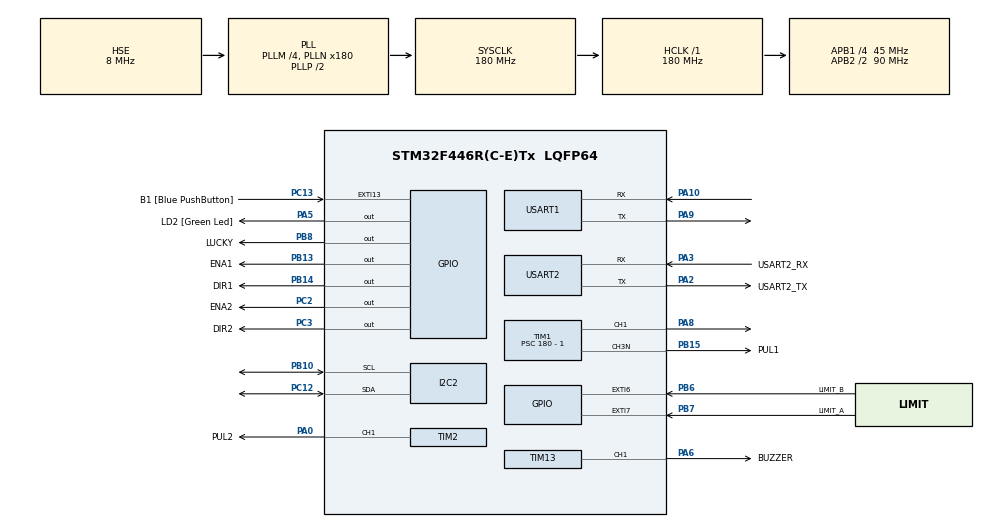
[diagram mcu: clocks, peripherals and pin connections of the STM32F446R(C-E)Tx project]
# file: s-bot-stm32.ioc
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Dma.I2C2_TX.3.Direction=DMA_MEMORY_TO_PERIPH
Dma.I2C2_TX.3.FIFOMode=DMA_FIFOMODE_DISABLE
Dma.I2C2_TX.3.Instance=DMA1_Stream7
Dma.I2C2_TX.3.MemDataAlignment=DMA_MDATAALIGN_BYTE
Dma.I2C2_TX.3.MemInc=DMA_MINC_ENABLE
Dma.I2C2_TX.3.Mode=DMA_NORMAL
Dma.I2C2_TX.3.PeriphDataAlignment=DMA_PDATAALIGN_BYTE
Dma.I2C2_TX.3.PeriphInc=DMA_PINC_DISABLE
Dma.I2C2_TX.3.Priority=DMA_PRIORITY_LOW
Dma.Request0=USART2_RX
Dma.Request1=USART1_TX
Dma.Request2=USART2_TX
Dma.Request3=I2C2_TX
Dma.Request4=USART1_RX
Dma.USART1_RX.4.Direction=DMA_PERIPH_TO_MEMORY
Dma.USART1_RX.4.FIFOMode=DMA_FIFOMODE_DISABLE
Dma.USART1_RX.4.Instance=DMA2_Stream2
Dma.USART1_RX.4.MemDataAlignment=DMA_MDATAALIGN_BYTE
Dma.USART1_RX.4.MemInc=DMA_MINC_ENABLE
Dma.USART1_RX.4.Mode=DMA_NORMAL
Dma.USART1_RX.4.PeriphDataAlignment=DMA_PDATAALIGN_BYTE
Dma.USART1_RX.4.PeriphInc=DMA_PINC_DISABLE
Dma.USART1_RX.4.Priority=DMA_PRIORITY_LOW
Dma.USART1_TX.1.Direction=DMA_MEMORY_TO_PERIPH
Dma.USART1_TX.1.FIFOMode=DMA_FIFOMODE_DISABLE
Dma.USART1_TX.1.Instance=DMA2_Stream7
Dma.USART1_TX.1.MemDataAlignment=DMA_MDATAALIGN_BYTE
Dma.USART1_TX.1.MemInc=DMA_MINC_ENABLE
Dma.USART1_TX.1.Mode=DMA_NORMAL
Dma.USART1_TX.1.PeriphDataAlignment=DMA_PDATAALIGN_BYTE
Dma.USART1_TX.1.PeriphInc=DMA_PINC_DISABLE
Dma.USART1_TX.1.Priority=DMA_PRIORITY_LOW
Dma.USART2_RX.0.Direction=DMA_PERIPH_TO_MEMORY
Dma.USART2_RX.0.FIFOMode=DMA_FIFOMODE_DISABLE
Dma.USART2_RX.0.Instance=DMA1_Stream5
Dma.USART2_RX.0.MemDataAlignment=DMA_MDATAALIGN_BYTE
Dma.USART2_RX.0.MemInc=DMA_MINC_ENABLE
Dma.USART2_RX.0.Mode=DMA_NORMAL
Dma.USART2_RX.0.PeriphDataAlignment=DMA_PDATAALIGN_BYTE
Dma.USART2_RX.0.PeriphInc=DMA_PINC_DISABLE
Dma.USART2_RX.0.Priority=DMA_PRIORITY_LOW
Dma.USART2_TX.2.Direction=DMA_MEMORY_TO_PERIPH
Dma.USART2_TX.2.FIFOMode=DMA_FIFOMODE_DISABLE
Dma.USART2_TX.2.Instance=DMA1_Stream6
Dma.USART2_TX.2.MemDataAlignment=DMA_MDATAALIGN_BYTE
Dma.USART2_TX.2.MemInc=DMA_MINC_ENABLE
Dma.USART2_TX.2.Mode=DMA_NORMAL
Dma.USART2_TX.2.PeriphDataAlignment=DMA_PDATAALIGN_BYTE
Dma.USART2_TX.2.PeriphInc=DMA_PINC_DISABLE
Dma.USART2_TX.2.Priority=DMA_PRIORITY_LOW
FREERTOS.Tasks01=LEDblinkTask,24,128,LEDblink,Default,NULL,Dynamic,NULL,NULL;OLEDdisplayTask,8,128,OLEDdisplay,As weak,NULL,Dynamic,NULL,NULL;StepperTask,8,128,Stepper,As weak,NULL,Dynamic,NULL,NULL;RobotStateTask,40,300,StateUpdate,As weak,NULL,Dynamic,NULL,NULL
FREERTOS.Timers01=OLED_Tx_Timeout,OLED_Tx_Timeout_Callback,osTimerOnce,As weak,NULL,Dynamic,NULL;OLED_Warning_Timeout,OLED_Warning_Timeout_Callback,osTimerOnce,As weak,NULL,Dynamic,NULL;OLED_Rx_Timeout,OLED_Rx_Timeout_Callback,osTimerOnce,As weak,NULL,Dynamic,NULL;USB_Hello,USB_Hello_Callback,osTimerPeriodic,As weak,NULL,Dynamic,NULL;Buzzer_Timeout,Buzzer_Timeout_Callback,osTimerOnce,As weak,NULL,Dynamic,NULL;Force_Sensor_Request_Timeout,Force_Sensor_Request_Timeout_Callback,osTimerPeriodic,As weak,NULL,Dynamic,NULL
Mcu.Family=STM32F4
Mcu.Name=STM32F446R(C-E)Tx
Mcu.Package=LQFP64
NVIC.DMA1_Stream5_IRQn=true\:5\:0\:false\:false\:true\:true\:false\:true\:true
NVIC.DMA1_Stream6_IRQn=true\:5\:0\:false\:false\:true\:true\:false\:true\:true
NVIC.DMA1_Stream7_IRQn=true\:5\:0\:false\:false\:true\:true\:false\:true\:true
NVIC.DMA2_Stream2_IRQn=true\:5\:0\:false\:false\:true\:true\:false\:true\:true
NVIC.DMA2_Stream7_IRQn=true\:5\:0\:false\:false\:true\:true\:false\:true\:true
NVIC.EXTI15_10_IRQn=true\:5\:0\:false\:false\:true\:true\:true\:true\:true
NVIC.EXTI9_5_IRQn=true\:5\:0\:true\:false\:true\:false\:true\:true\:true
NVIC.I2C2_EV_IRQn=true\:5\:0\:false\:false\:true\:true\:true\:true\:true
NVIC.PriorityGroup=NVIC_PRIORITYGROUP_4
NVIC.TIM1_BRK_TIM9_IRQn=true\:5\:0\:false\:false\:true\:true\:true\:true\:true
NVIC.TIM1_CC_IRQn=true\:5\:0\:false\:false\:true\:true\:true\:true\:true
NVIC.TIM1_UP_TIM10_IRQn=true\:5\:0\:false\:false\:true\:true\:true\:true\:true
NVIC.TIM2_IRQn=true\:5\:0\:false\:false\:true\:true\:true\:true\:true
NVIC.TIM8_TRG_COM_TIM14_IRQn=true\:15\:0\:false\:false\:true\:false\:false\:true\:true
NVIC.TimeBase=TIM8_TRG_COM_TIM14_IRQn
NVIC.TimeBaseIP=TIM14
NVIC.USART1_IRQn=true\:5\:0\:false\:false\:true\:true\:true\:true\:true
NVIC.USART2_IRQn=true\:5\:0\:false\:false\:true\:true\:true\:true\:true
PA0-WKUP.GPIO_Label=PUL2
PA0-WKUP.GPIO_PuPd=GPIO_PULLDOWN
PA0-WKUP.Signal=S_TIM2_CH1_ETR
PA10.Mode=Asynchronous
PA10.Signal=USART1_RX
PA13.GPIO_Label=TMS
PA13.Mode=Serial_Wire
PA13.Signal=SYS_JTMS-SWDIO
PA14.GPIO_Label=TCK
PA14.Mode=Serial_Wire
PA14.Signal=SYS_JTCK-SWCLK
PA2.GPIO_Label=USART2_TX
PA2.Mode=Asynchronous
PA2.Signal=USART2_TX
PA3.GPIO_Label=USART2_RX
PA3.Mode=Asynchronous
PA3.Signal=USART2_RX
PA5.GPIO_Label=LD2 [Green Led]
PA5.Signal=GPIO_Output
PA6.GPIO_Label=BUZZER
PA6.Signal=S_TIM13_CH1
PA8.GPIO_PuPd=GPIO_PULLDOWN
PA8.Signal=S_TIM1_CH1
PA9.Mode=Asynchronous
PA9.Signal=USART1_TX
PB10.Mode=I2C
PB10.Signal=I2C2_SCL
PB13.GPIO_Label=ENA1
PB13.Signal=GPIO_Output
PB14.GPIO_Label=DIR1
PB14.Signal=GPIO_Output
PB15.GPIO_Label=PUL1
PB15.GPIO_PuPd=GPIO_PULLDOWN
PB15.Mode=PWM Generation3 CH3N
PB15.Signal=TIM1_CH3N
PB3.GPIO_Label=SWO
PB3.Signal=SYS_JTDO-SWO
PB6.GPIO_Label=LIMIT_B
PB6.GPIO_PuPd=GPIO_PULLUP
PB6.Signal=GPXTI6
PB7.GPIO_Label=LIMIT_A
PB7.GPIO_ModeDefaultEXTI=GPIO_MODE_IT_FALLING
PB7.GPIO_PuPd=GPIO_PULLUP
PB7.Signal=GPXTI7
PB8.GPIO_Label=LUCKY
PB8.Signal=GPIO_Output
PC12.Mode=I2C
PC12.Signal=I2C2_SDA
PC13.GPIO_Label=B1 [Blue PushButton]
PC13.GPIO_ModeDefaultEXTI=GPIO_MODE_IT_FALLING
PC13.Signal=GPXTI13
PC14-OSC32_IN.Mode=LSE-External-Oscillator
PC14-OSC32_IN.Signal=RCC_OSC32_IN
PC15-OSC32_OUT.Mode=LSE-External-Oscillator
PC15-OSC32_OUT.Signal=RCC_OSC32_OUT
PC2.GPIO_Label=ENA2
PC2.Signal=GPIO_Output
PC3.GPIO_Label=DIR2
PC3.Signal=GPIO_Output
PH0-OSC_IN.Mode=HSE-External-Oscillator
PH0-OSC_IN.Signal=RCC_OSC_IN
PH1-OSC_OUT.Mode=HSE-External-Oscillator
PH1-OSC_OUT.Signal=RCC_OSC_OUT
ProjectManager.HeapSize=0x200
ProjectManager.StackSize=0x400
ProjectManager.TargetToolchain=STM32CubeIDE
RCC.48MHZClocksFreq_Value=84000000
RCC.AHBFreq_Value=180000000
RCC.APB1CLKDivider=RCC_HCLK_DIV4
RCC.APB1Freq_Value=45000000
RCC.APB1TimFreq_Value=90000000
RCC.APB2CLKDivider=RCC_HCLK_DIV2
RCC.APB2Freq_Value=90000000
RCC.APB2TimFreq_Value=180000000
RCC.CortexFreq_Value=180000000
RCC.FLatency-AdvancedSettings=FLASH_LATENCY_5
RCC.HCLKFreq_Value=180000000
RCC.HSE_VALUE=8000000
RCC.HSI_VALUE=16000000
RCC.PLLM=4
RCC.PLLN=180
RCC.PLLSourceVirtual=RCC_PLLSOURCE_HSE
RCC.SYSCLKFreq_VALUE=180000000
RCC.SYSCLKSource=RCC_SYSCLKSOURCE_PLLCLK
RCC.USBFreq_Value=180000000
RCC.VCOOutputFreq_Value=360000000
SH.S_TIM13_CH1.0=TIM13_CH1,PWM Generation1 CH1
SH.S_TIM1_CH1.0=TIM1_CH1,PWM Generation1 CH1
SH.S_TIM2_CH1_ETR.0=TIM2_CH1,PWM Generation1 CH1
TIM1.Channel-PWM\ Generation1\ CH1=TIM_CHANNEL_1
TIM1.Channel-PWM\ Generation3\ CH3N=TIM_CHANNEL_3
TIM1.OC3Preload_PWM=DISABLE
TIM1.OCFastMode_PWM-PWM\ Generation3\ CH3N=TIM_OCFAST_ENABLE
TIM1.OCMode_PWM-PWM\ Generation1\ CH1=TIM_OCMODE_PWM2
TIM1.OCMode_PWM-PWM\ Generation3\ CH3N=TIM_OCMODE_PWM2
TIM1.OCNPolarity_3=TIM_OCNPOLARITY_LOW
TIM1.OCPolarity_1=TIM_OCPOLARITY_LOW
TIM1.Period=100 - 1
TIM1.Prescaler=180 - 1
TIM1.Pulse-PWM\ Generation1\ CH1=10
TIM1.Pulse-PWM\ Generation3\ CH3N=10
TIM1.TIM_MasterOutputTrigger=TIM_TRGO_RESET
TIM13.Channel=TIM_CHANNEL_1
TIM13.Period=256 - 1
TIM13.Prescaler=256 - 1
TIM13.Pulse=10
TIM2.Channel-PWM\ Generation1\ CH1=TIM_CHANNEL_1
TIM2.CounterMode=TIM_COUNTERMODE_CENTERALIGNED1
TIM2.OCMode_PWM-PWM\ Generation1\ CH1=TIM_OCMODE_PWM2
TIM2.OCPolarity_1=TIM_OCPOLARITY_LOW
TIM2.Period=1000 - 1
TIM2.Prescaler=180 - 1
TIM2.Pulse-PWM\ Generation1\ CH1=10
USART1.VirtualMode=VM_ASYNC
USART2.VirtualMode=VM_ASYNC
VP_FREERTOS_VS_CMSIS_V2.Mode=CMSIS_V2
VP_SYS_VS_tim14.Mode=TIM14
VP_TIM13_VS_ClockSourceINT.Mode=Enable_Timer
VP_TIM1_VS_ClockSourceINT.Mode=Internal
VP_TIM2_VS_ClockSourceINT.Mode=Internal
board=NUCLEO-F446RE

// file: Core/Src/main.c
/* USER CODE BEGIN Header */
/**
 ******************************************************************************
 * @file           : main.c
 * @brief          : Main program body
 ******************************************************************************
 * @attention
 *
 * Copyright (c) 2022 STMicroelectronics.
 * All rights reserved.
 *
 * This software is licensed under terms that can be found in the LICENSE file
 * in the root directory of this software component.
 * If no LICENSE file comes with this software, it is provided AS-IS.
 *
 ******************************************************************************
 */
/* USER CODE END Header */
#include "main.h"
#include "cmsis_os.h"
#include "dma.h"
#include "i2c.h"
#include "tim.h"
#include "usart.h"
#include "gpio.h"

/* USER CODE BEGIN Includes */
#include "robot.h"
/* USER CODE END Includes */

void SystemClock_Config(void);
void MX_FREERTOS_Init(void);

int main(void)
{

  /* MCU Configuration--------------------------------------------------------*/

  /* Reset of all peripherals, Initializes the Flash interface and the Systick. */
  HAL_Init();

  /* Configure the system clock */
  SystemClock_Config();

  /* Initialize all configured peripherals */
  MX_GPIO_Init();
  MX_DMA_Init();
  MX_I2C2_Init();
  MX_USART1_UART_Init();
  MX_USART2_UART_Init();
  MX_TIM13_Init();
  MX_TIM1_Init();
  MX_TIM2_Init();
  /* USER CODE BEGIN 2 */
  USBserial_Init();
  OLED_Init();
  State_Init();
  /* USER CODE END 2 */

  /* Init scheduler */
  osKernelInitialize();  /* Call init function for freertos objects (in freertos.c) */
  MX_FREERTOS_Init();

  /* Start scheduler */
  osKernelStart();

  /* We should never get here as control is now taken by the scheduler */
  /* Infinite loop */
  while (1)
  {

  }
}

void SystemClock_Config(void)
{
  RCC_OscInitTypeDef RCC_OscInitStruct = {0};
  RCC_ClkInitTypeDef RCC_ClkInitStruct = {0};

  /** Configure the main internal regulator output voltage
  */
  __HAL_RCC_PWR_CLK_ENABLE();
  __HAL_PWR_VOLTAGESCALING_CONFIG(PWR_REGULATOR_VOLTAGE_SCALE1);

  /** Initializes the RCC Oscillators according to the specified parameters
  * in the RCC_OscInitTypeDef structure.
  */
  RCC_OscInitStruct.OscillatorType = RCC_OSCILLATORTYPE_HSE;
  RCC_OscInitStruct.HSEState = RCC_HSE_ON;
  RCC_OscInitStruct.PLL.PLLState = RCC_PLL_ON;
  RCC_OscInitStruct.PLL.PLLSource = RCC_PLLSOURCE_HSE;
  RCC_OscInitStruct.PLL.PLLM = 4;
  RCC_OscInitStruct.PLL.PLLN = 180;
  RCC_OscInitStruct.PLL.PLLP = RCC_PLLP_DIV2;
  RCC_OscInitStruct.PLL.PLLQ = 2;
  RCC_OscInitStruct.PLL.PLLR = 2;
  if (HAL_RCC_OscConfig(&RCC_OscInitStruct) != HAL_OK)
  {
    Error_Handler();
  }

  /** Activate the Over-Drive mode
  */
  if (HAL_PWREx_EnableOverDrive() != HAL_OK)
  {
    Error_Handler();
  }

  /** Initializes the CPU, AHB and APB buses clocks
  */
  RCC_ClkInitStruct.ClockType = RCC_CLOCKTYPE_HCLK|RCC_CLOCKTYPE_SYSCLK
                              |RCC_CLOCKTYPE_PCLK1|RCC_CLOCKTYPE_PCLK2;
  RCC_ClkInitStruct.SYSCLKSource = RCC_SYSCLKSOURCE_PLLCLK;
  RCC_ClkInitStruct.AHBCLKDivider = RCC_SYSCLK_DIV1;
  RCC_ClkInitStruct.APB1CLKDivider = RCC_HCLK_DIV4;
  RCC_ClkInitStruct.APB2CLKDivider = RCC_HCLK_DIV2;

  if (HAL_RCC_ClockConfig(&RCC_ClkInitStruct, FLASH_LATENCY_5) != HAL_OK)
  {
    Error_Handler();
  }
}

void HAL_TIM_PeriodElapsedCallback(TIM_HandleTypeDef *htim)
{
  if (htim->Instance == TIM14) {
    HAL_IncTick();
  }
}

void Error_Handler(void)
{
  __disable_irq();
  while (1)
  {
  }
}

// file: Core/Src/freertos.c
/* USER CODE BEGIN Header */
/**
 ******************************************************************************
 * File Name          : freertos.c
 * Description        : Code for freertos applications
 ******************************************************************************
 * @attention
 *
 * Copyright (c) 2022 STMicroelectronics.
 * All rights reserved.
 *
 * This software is licensed under terms that can be found in the LICENSE file
 * in the root directory of this software component.
 * If no LICENSE file comes with this software, it is provided AS-IS.
 *
 ******************************************************************************
 */
/* USER CODE END Header */

#include "FreeRTOS.h"
#include "task.h"
#include "main.h"
#include "cmsis_os.h"

/* USER CODE BEGIN Includes */
#include "robot.h"
/* USER CODE END Includes */

/* Definitions for LEDblinkTask */
osThreadId_t LEDblinkTaskHandle;
const osThreadAttr_t LEDblinkTask_attributes = {
  .name = "LEDblinkTask",
  .stack_size = 128 * 4,
  .priority = (osPriority_t) osPriorityNormal,
};
/* Definitions for OLEDdisplayTask */
osThreadId_t OLEDdisplayTaskHandle;
const osThreadAttr_t OLEDdisplayTask_attributes = {
  .name = "OLEDdisplayTask",
  .stack_size = 128 * 4,
  .priority = (osPriority_t) osPriorityLow,
};
/* Definitions for StepperTask */
osThreadId_t StepperTaskHandle;
const osThreadAttr_t StepperTask_attributes = {
  .name = "StepperTask",
  .stack_size = 128 * 4,
  .priority = (osPriority_t) osPriorityLow,
};
/* Definitions for RobotStateTask */
osThreadId_t RobotStateTaskHandle;
const osThreadAttr_t RobotStateTask_attributes = {
  .name = "RobotStateTask",
  .stack_size = 300 * 4,
  .priority = (osPriority_t) osPriorityHigh,
};
/* Definitions for OLED_Tx_Timeout */
osTimerId_t OLED_Tx_TimeoutHandle;
const osTimerAttr_t OLED_Tx_Timeout_attributes = {
  .name = "OLED_Tx_Timeout"
};
/* Definitions for OLED_Warning_Timeout */
osTimerId_t OLED_Warning_TimeoutHandle;
const osTimerAttr_t OLED_Warning_Timeout_attributes = {
  .name = "OLED_Warning_Timeout"
};
/* Definitions for OLED_Rx_Timeout */
osTimerId_t OLED_Rx_TimeoutHandle;
const osTimerAttr_t OLED_Rx_Timeout_attributes = {
  .name = "OLED_Rx_Timeout"
};
/* Definitions for USB_Hello */
osTimerId_t USB_HelloHandle;
const osTimerAttr_t USB_Hello_attributes = {
  .name = "USB_Hello"
};
/* Definitions for Buzzer_Timeout */
osTimerId_t Buzzer_TimeoutHandle;
const osTimerAttr_t Buzzer_Timeout_attributes = {
  .name = "Buzzer_Timeout"
};
/* Definitions for Force_Sensor_Request_Timeout */
osTimerId_t Force_Sensor_Request_TimeoutHandle;
const osTimerAttr_t Force_Sensor_Request_Timeout_attributes = {
  .name = "Force_Sensor_Request_Timeout"
};

void LEDblink(void *argument);
void OLEDdisplay(void *argument);
void Stepper(void *argument);
void StateUpdate(void *argument);
void OLED_Tx_Timeout_Callback(void *argument);
void OLED_Warning_Timeout_Callback(void *argument);
void OLED_Rx_Timeout_Callback(void *argument);
void USB_Hello_Callback(void *argument);
void Buzzer_Timeout_Callback(void *argument);
void Force_Sensor_Request_Timeout_Callback(void *argument);

void MX_FREERTOS_Init(void); /* (MISRA C 2004 rule 8.1) */

void MX_FREERTOS_Init(void) {

  /* Create the timer(s) */
  /* creation of OLED_Tx_Timeout */
  OLED_Tx_TimeoutHandle = osTimerNew(OLED_Tx_Timeout_Callback, osTimerOnce, NULL, &OLED_Tx_Timeout_attributes);

  /* creation of OLED_Warning_Timeout */
  OLED_Warning_TimeoutHandle = osTimerNew(OLED_Warning_Timeout_Callback, osTimerOnce, NULL, &OLED_Warning_Timeout_attributes);

  /* creation of OLED_Rx_Timeout */
  OLED_Rx_TimeoutHandle = osTimerNew(OLED_Rx_Timeout_Callback, osTimerOnce, NULL, &OLED_Rx_Timeout_attributes);

  /* creation of USB_Hello */
  USB_HelloHandle = osTimerNew(USB_Hello_Callback, osTimerPeriodic, NULL, &USB_Hello_attributes);

  /* creation of Buzzer_Timeout */
  Buzzer_TimeoutHandle = osTimerNew(Buzzer_Timeout_Callback, osTimerOnce, NULL, &Buzzer_Timeout_attributes);

  /* creation of Force_Sensor_Request_Timeout */
  Force_Sensor_Request_TimeoutHandle = osTimerNew(Force_Sensor_Request_Timeout_Callback, osTimerPeriodic, NULL, &Force_Sensor_Request_Timeout_attributes);

  /* Create the thread(s) */
  /* creation of LEDblinkTask */
  LEDblinkTaskHandle = osThreadNew(LEDblink, NULL, &LEDblinkTask_attributes);

  /* creation of OLEDdisplayTask */
  OLEDdisplayTaskHandle = osThreadNew(OLEDdisplay, NULL, &OLEDdisplayTask_attributes);

  /* creation of StepperTask */
  StepperTaskHandle = osThreadNew(Stepper, NULL, &StepperTask_attributes);

  /* creation of RobotStateTask */
  RobotStateTaskHandle = osThreadNew(StateUpdate, NULL, &RobotStateTask_attributes);

}

void LEDblink(void *argument)
{
  /* USER CODE BEGIN LEDblink */
  Force_Sensor_Init();
  // Ringbuf_Init();
  beep(2);
  /* Infinite loop */
  for (;;)
  {
    HAL_GPIO_TogglePin(LD2_GPIO_Port, LD2_Pin);
    osDelay(1000);
  }
  /* USER CODE END LEDblink */
}

__weak void OLEDdisplay(void *argument)
{
  for (;;)
  {
    osDelay(1);
  }
}

__weak void Stepper(void *argument)
{
  for (;;)
  {
    osDelay(1);
  }
}

__weak void StateUpdate(void *argument)
{
  for (;;)
  {
    osDelay(1);
  }
}

/* OLED_Tx_Timeout_Callback function */
__weak void OLED_Tx_Timeout_Callback(void *argument)
{
}

/* OLED_Warning_Timeout_Callback function */
__weak void OLED_Warning_Timeout_Callback(void *argument)
{
}

/* OLED_Rx_Timeout_Callback function */
__weak void OLED_Rx_Timeout_Callback(void *argument)
{
}

/* USB_Hello_Callback function */
__weak void USB_Hello_Callback(void *argument)
{
}

/* Buzzer_Timeout_Callback function */
__weak void Buzzer_Timeout_Callback(void *argument)
{
}

/* Force_Sensor_Request_Timeout_Callback function */
__weak void Force_Sensor_Request_Timeout_Callback(void *argument)
{
}
